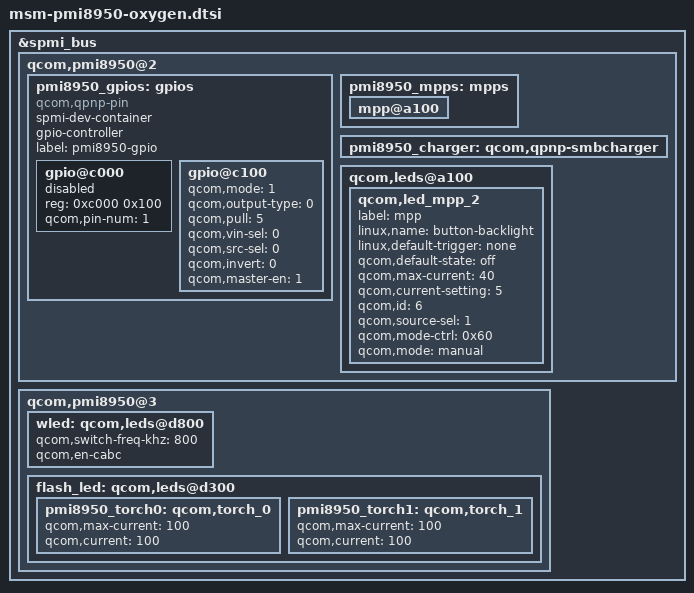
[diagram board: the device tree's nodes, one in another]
/* Copyright (c) 2015-2017, The Linux Foundation. All rights reserved.
 *
 * This program is free software; you can redistribute it and/or modify
 * it under the terms of the GNU General Public License version 2 and
 * only version 2 as published by the Free Software Foundation.
 *
 * This program is distributed in the hope that it will be useful,
 * but WITHOUT ANY WARRANTY; without even the implied warranty of
 * MERCHANTABILITY or FITNESS FOR A PARTICULAR PURPOSE.  See the
 * GNU General Public License for more details.
 */

&spmi_bus {
	qcom,pmi8950@2 {
		pmi8950_gpios: gpios {
			spmi-dev-container;
			compatible = "qcom,qpnp-pin";
			gpio-controller;
			#gpio-cells = <2>;
			#address-cells = <1>;
			#size-cells = <1>;
			label = "pmi8950-gpio";

			gpio@c000 {
				reg = <0xc000 0x100>;
				qcom,pin-num = <1>;
				status = "disabled";
			};

			gpio@c100 {
				qcom,mode = <1>;	/* Digital output */
				qcom,output-type = <0>;	/* CMOS */
				qcom,pull = <5>;	/* No pull */
				qcom,vin-sel = <0>;	/* VIN0 */
				qcom,src-sel = <0>;	/* Constant */
				qcom,invert = <0>;	/* Output low initially */
				qcom,master-en = <1>;	/* GPIO enabled */
				status = "okay";
			};
		};

		pmi8950_mpps: mpps {
			mpp@a100 {
				status = "okay";
			};
		};

		pmi8950_charger: qcom,qpnp-smbcharger {
			/delete-property/ qcom,autoadjust-vfloat;
		};

		qcom,leds@a100 {
			qcom,led_mpp_2 {
				label = "mpp";
				linux,name = "button-backlight";
				linux,default-trigger = "none";
				qcom,default-state = "off";
				qcom,max-current = <40>;
				qcom,current-setting = <5>;
				qcom,id = <6>;
				qcom,source-sel = <1>;
				qcom,mode-ctrl = <0x60>;
				qcom,mode = "manual";
			};
		};
	};

	qcom,pmi8950@3 {
		wled: qcom,leds@d800 {
			qcom,switch-freq-khz = <800>;
			/delete-property/ qcom,en-ext-pfet-sc-pro;
			qcom,en-cabc;
		};

		flash_led: qcom,leds@d300 {
			pmi8950_torch0: qcom,torch_0 {
				qcom,max-current = <100>;
				qcom,current = <100>;
			};

			pmi8950_torch1: qcom,torch_1 {
				qcom,max-current = <100>;
				qcom,current = <100>;
			};
		};
	};
};
